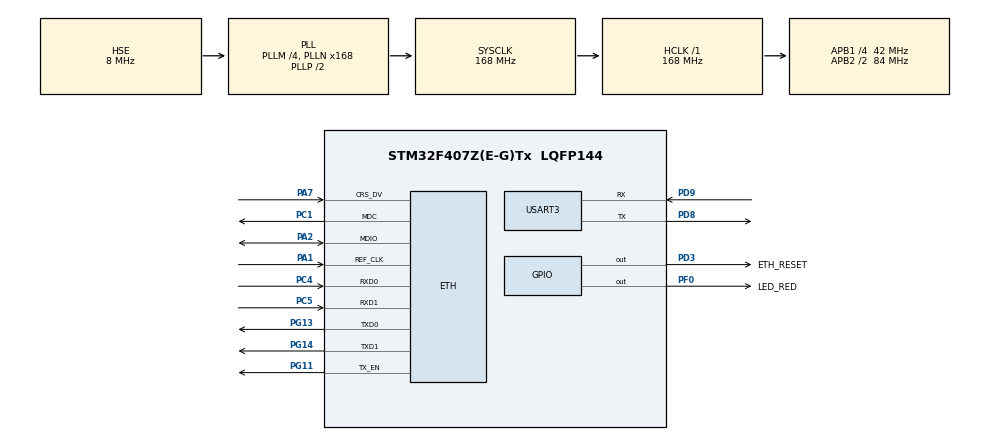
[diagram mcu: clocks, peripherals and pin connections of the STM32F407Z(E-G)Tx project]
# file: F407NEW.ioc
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ETH.MediaInterface=ETH_MEDIA_INTERFACE_RMII
ETH.PHY_Name_RMII=userPHY
ETH.PHY_User_Name=LAN8720A
ETH.PhyAddress=0
FREERTOS.Tasks01=SCI,3,256,SCI_FUNC,Default,NULL,Dynamic,NULL,NULL;NET,3,256,NET_FUNC,Default,NULL,Dynamic,NULL,NULL;LED,-2,128,LED_FUNC,Default,NULL,Dynamic,NULL,NULL
FREERTOS.configMAX_PRIORITIES=12
FREERTOS.configTOTAL_HEAP_SIZE=49152
LWIP.GATEWAY_ADDRESS=192.168.001.001
LWIP.IP_ADDRESS=192.168.001.028
LWIP.LWIP_DHCP=0
LWIP.LWIP_NETIF_LINK_CALLBACK=1
LWIP.LWIP_NETIF_STATUS_CALLBACK=1
LWIP.LWIP_UDP=0
LWIP.NETMASK_ADDRESS=255.255.255.000
LWIP.Version=v2.0.3_Cube
Mcu.Family=STM32F4
Mcu.Name=STM32F407Z(E-G)Tx
Mcu.Package=LQFP144
NVIC.ETH_IRQn=true\:5\:0\:true\:false\:true\:true\:true\:true
NVIC.PriorityGroup=NVIC_PRIORITYGROUP_4
NVIC.TIM1_UP_TIM10_IRQn=true\:0\:0\:false\:false\:true\:false\:false\:true
NVIC.TimeBase=TIM1_UP_TIM10_IRQn
NVIC.TimeBaseIP=TIM1
NVIC.USART3_IRQn=true\:5\:0\:true\:false\:true\:true\:true\:true
PA1.Mode=RMII
PA1.Signal=ETH_REF_CLK
PA13.Mode=Serial_Wire
PA13.Signal=SYS_JTMS-SWDIO
PA14.Mode=Serial_Wire
PA14.Signal=SYS_JTCK-SWCLK
PA2.Mode=RMII
PA2.Signal=ETH_MDIO
PA7.Mode=RMII
PA7.Signal=ETH_CRS_DV
PB11.Signal=S_TIM2_CH4
PC1.Mode=RMII
PC1.Signal=ETH_MDC
PC4.Mode=RMII
PC4.Signal=ETH_RXD0
PC5.Mode=RMII
PC5.Signal=ETH_RXD1
PD3.GPIO_Label=ETH_RESET
PD3.GPIO_Speed=GPIO_SPEED_FREQ_VERY_HIGH
PD3.PinState=GPIO_PIN_SET
PD3.Signal=GPIO_Output
PD8.Mode=Asynchronous
PD8.Signal=USART3_TX
PD9.Mode=Asynchronous
PD9.Signal=USART3_RX
PF0.GPIO_Label=LED_RED
PF0.Signal=GPIO_Output
PG11.Mode=RMII
PG11.Signal=ETH_TX_EN
PG13.Mode=RMII
PG13.Signal=ETH_TXD0
PG14.Mode=RMII
PG14.Signal=ETH_TXD1
PH0-OSC_IN.Mode=HSE-External-Oscillator
PH0-OSC_IN.Signal=RCC_OSC_IN
PH1-OSC_OUT.Mode=HSE-External-Oscillator
PH1-OSC_OUT.Signal=RCC_OSC_OUT
ProjectManager.HeapSize=0x200
ProjectManager.StackSize=0x4000
ProjectManager.TargetToolchain=MDK-ARM V5
RCC.48MHZClocksFreq_Value=84000000
RCC.AHBFreq_Value=168000000
RCC.APB1CLKDivider=RCC_HCLK_DIV4
RCC.APB1Freq_Value=42000000
RCC.APB1TimFreq_Value=84000000
RCC.APB2CLKDivider=RCC_HCLK_DIV2
RCC.APB2Freq_Value=84000000
RCC.APB2TimFreq_Value=168000000
RCC.CortexFreq_Value=168000000
RCC.HCLKFreq_Value=168000000
RCC.HSE_VALUE=8000000
RCC.HSI_VALUE=16000000
RCC.LSE_VALUE=32768
RCC.PLLM=4
RCC.PLLN=168
RCC.PLLSourceVirtual=RCC_PLLSOURCE_HSE
RCC.SYSCLKFreq_VALUE=168000000
RCC.SYSCLKSource=RCC_SYSCLKSOURCE_PLLCLK
RCC.VCOOutputFreq_Value=336000000
SH.S_TIM2_CH4.0=TIM2_CH4
USART3.VirtualMode=VM_ASYNC
VP_FREERTOS_VS_CMSIS_V1.Mode=CMSIS_V1
VP_LWIP_VS_Enabled.Mode=Enabled
VP_SYS_VS_tim1.Mode=TIM1
board=custom

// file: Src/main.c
/* USER CODE BEGIN Header */
/**
  ******************************************************************************
  * @file           : main.c
  * @brief          : Main program body
  ******************************************************************************
  * @attention
  *
  * <h2><center>&copy; Copyright (c) 2025 STMicroelectronics.
  * All rights reserved.</center></h2>
  *
  * This software component is licensed by ST under Ultimate Liberty license
  * SLA0044, the "License"; You may not use this file except in compliance with
  * the License. You may obtain a copy of the License at:
  *                             www.st.com/SLA0044
  *
  ******************************************************************************
  */
/* USER CODE END Header */

#include "main.h"
#include "cmsis_os.h"
#include "lwip.h"
#include "usart.h"
#include "gpio.h"

/* USER CODE BEGIN Includes */
#include <string.h>

/* USER CODE END Includes */

/* USER CODE BEGIN PV */

// #define RXBUFFERSIZE  256     //最大接收字节数
// char RxBuffer[RXBUFFERSIZE];   //接收数据
// uint8_t aRxBuffer;			//接收中断缓冲
// uint8_t Uart3_Rx_Cnt = 0;		//接收缓冲计数

/* USER CODE END PV */

void SystemClock_Config(void);
void MX_FREERTOS_Init(void);

int main(void)
{

  /* MCU Configuration--------------------------------------------------------*/

  /* Reset of all peripherals, Initializes the Flash interface and the Systick. */
  HAL_Init();

  /* Configure the system clock */
  SystemClock_Config();

  /* Initialize all configured peripherals */
  MX_GPIO_Init();
  MX_USART3_UART_Init();
  /* USER CODE BEGIN 2 */

	// HAL_UART_Receive_IT(&huart3, (uint8_t *)&aRxBuffer, 1);
  /* init code for LWIP */
  MX_LWIP_Init();
	tcpecho_init();
	printf("RTOS_LWIP: Start\r\n");

  /* USER CODE END 2 */

  /* Call init function for freertos objects (in freertos.c) */
  MX_FREERTOS_Init();

  /* Start scheduler */
  osKernelStart();

  /* We should never get here as control is now taken by the scheduler */

  /* Infinite loop */
  while (1)
  {

  }
}

void SystemClock_Config(void)
{
  RCC_OscInitTypeDef RCC_OscInitStruct = {0};
  RCC_ClkInitTypeDef RCC_ClkInitStruct = {0};

  /** Configure the main internal regulator output voltage
  */
  __HAL_RCC_PWR_CLK_ENABLE();
  __HAL_PWR_VOLTAGESCALING_CONFIG(PWR_REGULATOR_VOLTAGE_SCALE1);
  /** Initializes the CPU, AHB and APB busses clocks
  */
  RCC_OscInitStruct.OscillatorType = RCC_OSCILLATORTYPE_HSE;
  RCC_OscInitStruct.HSEState = RCC_HSE_ON;
  RCC_OscInitStruct.PLL.PLLState = RCC_PLL_ON;
  RCC_OscInitStruct.PLL.PLLSource = RCC_PLLSOURCE_HSE;
  RCC_OscInitStruct.PLL.PLLM = 4;
  RCC_OscInitStruct.PLL.PLLN = 168;
  RCC_OscInitStruct.PLL.PLLP = RCC_PLLP_DIV2;
  RCC_OscInitStruct.PLL.PLLQ = 4;
  if (HAL_RCC_OscConfig(&RCC_OscInitStruct) != HAL_OK)
  {
    Error_Handler();
  }
  /** Initializes the CPU, AHB and APB busses clocks
  */
  RCC_ClkInitStruct.ClockType = RCC_CLOCKTYPE_HCLK|RCC_CLOCKTYPE_SYSCLK
                              |RCC_CLOCKTYPE_PCLK1|RCC_CLOCKTYPE_PCLK2;
  RCC_ClkInitStruct.SYSCLKSource = RCC_SYSCLKSOURCE_PLLCLK;
  RCC_ClkInitStruct.AHBCLKDivider = RCC_SYSCLK_DIV1;
  RCC_ClkInitStruct.APB1CLKDivider = RCC_HCLK_DIV4;
  RCC_ClkInitStruct.APB2CLKDivider = RCC_HCLK_DIV2;

  if (HAL_RCC_ClockConfig(&RCC_ClkInitStruct, FLASH_LATENCY_5) != HAL_OK)
  {
    Error_Handler();
  }
}

/* USER CODE BEGIN 4 */

void HAL_UART_RxCpltCallback(UART_HandleTypeDef *huart)
{
  /* Prevent unused argument(s) compilation warning */

	// if(Uart3_Rx_Cnt >= 255)  //溢出判断
	// {
	//  Uart3_Rx_Cnt = 0;
	//  memset(RxBuffer,0x00,sizeof(RxBuffer));
	//  HAL_UART_Transmit(&huart3, (uint8_t *)"数据溢出", 10,0xFFFF);
	// }
	// else
	// {
	//  RxBuffer[Uart3_Rx_Cnt++] = aRxBuffer;   //接收数据转存

	//  if((RxBuffer[Uart3_Rx_Cnt-1] == 0x0A)&&(RxBuffer[Uart3_Rx_Cnt-2] == 0x0D)) //判断结束位
	//  {
	// 	 HAL_UART_Transmit(&huart3, (uint8_t *)&RxBuffer, Uart3_Rx_Cnt,0xFFFF); //将收到的信息发送出去
	// 	 while(HAL_UART_GetState(&huart3) == HAL_UART_STATE_BUSY_TX);//检测UART发送结束
	// 	 Uart3_Rx_Cnt = 0;
	// 	 memset(RxBuffer,0x00,sizeof(RxBuffer)); //清空数组
	//  }
	// }
	// HAL_UART_Receive_IT(&huart3, (uint8_t *)&aRxBuffer, 1);   //再开启接收中断

}
/* USER CODE END 4 */

void HAL_TIM_PeriodElapsedCallback(TIM_HandleTypeDef *htim)
{
  if (htim->Instance == TIM1) {
    HAL_IncTick();
  }
}

void Error_Handler(void)
{
}

/************************ (C) COPYRIGHT STMicroelectronics *****END OF FILE****/

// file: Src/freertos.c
/* USER CODE BEGIN Header */
/**
  ******************************************************************************
  * File Name          : freertos.c
  * Description        : Code for freertos applications
  ******************************************************************************
  * @attention
  *
  * <h2><center>&copy; Copyright (c) 2025 STMicroelectronics.
  * All rights reserved.</center></h2>
  *
  * This software component is licensed by ST under Ultimate Liberty license
  * SLA0044, the "License"; You may not use this file except in compliance with
  * the License. You may obtain a copy of the License at:
  *                             www.st.com/SLA0044
  *
  ******************************************************************************
  */
/* USER CODE END Header */

#include "FreeRTOS.h"
#include "task.h"
#include "main.h"
#include "cmsis_os.h"

/* USER CODE BEGIN PM */
// extern char RxBuffer[256];   //接收数据
// extern uint8_t aRxBuffer;			//接收中断缓冲
// extern uint8_t Uart3_Rx_Cnt;		//接收缓冲计数
/* USER CODE END PM */

osThreadId LEDHandle;
osThreadId NETHandle;

/* USER CODE BEGIN FunctionPrototypes */
int num = 0;
/* USER CODE END FunctionPrototypes */

void LED_FUNC(void const * argument);
void NET_FUNC(void const * argument);

extern void MX_LWIP_Init(void);
void MX_FREERTOS_Init(void); /* (MISRA C 2004 rule 8.1) */

/* GetIdleTaskMemory prototype (linked to static allocation support) */
void vApplicationGetIdleTaskMemory( StaticTask_t **ppxIdleTaskTCBBuffer, StackType_t **ppxIdleTaskStackBuffer, uint32_t *pulIdleTaskStackSize );

/* USER CODE BEGIN GET_IDLE_TASK_MEMORY */
static StaticTask_t xIdleTaskTCBBuffer;
static StackType_t xIdleStack[configMINIMAL_STACK_SIZE];

void vApplicationGetIdleTaskMemory( StaticTask_t **ppxIdleTaskTCBBuffer, StackType_t **ppxIdleTaskStackBuffer, uint32_t *pulIdleTaskStackSize )
{
  *ppxIdleTaskTCBBuffer = &xIdleTaskTCBBuffer;
  *ppxIdleTaskStackBuffer = &xIdleStack[0];
  *pulIdleTaskStackSize = configMINIMAL_STACK_SIZE;
  /* place for user code */
}
/* USER CODE END GET_IDLE_TASK_MEMORY */

void MX_FREERTOS_Init(void) {

  /* Create the thread(s) */
  /* definition and creation of LED */
  osThreadDef(LED, LED_FUNC, osPriorityLow, 0, 128);
  LEDHandle = osThreadCreate(osThread(LED), NULL);

  /* definition and creation of NET */
  osThreadDef(NET, NET_FUNC, osPriorityRealtime, 0, 256);
  NETHandle = osThreadCreate(osThread(NET), NULL);

}

void LED_FUNC(void const * argument)
{
  /* USER CODE BEGIN LED_FUNC */
  /* Infinite loop */
  for(;;)
  {
		HAL_GPIO_TogglePin(LED_RED_GPIO_Port, LED_YELLOW_Pin);
    osDelay(1000);
  }
  /* USER CODE END LED_FUNC */
}

void NET_FUNC(void const * argument)
{
  /* USER CODE BEGIN NET_FUNC */
  /* Infinite loop */
  for(;;)
  {
  if(num == 0x55){
	//if(num == 0){
    HAL_GPIO_WritePin(LED_GREEN_GPIO_Port, LED_RED_Pin, GPIO_PIN_SET);//turn off
  }else if(num == 0xcc)
	//}else if(num == 1)
	{
    HAL_GPIO_WritePin(LED_GREEN_GPIO_Port, LED_RED_Pin, GPIO_PIN_RESET);//turn on
  }
    osDelay(1);
  }
  /* USER CODE END NET_FUNC */
}

/************************ (C) COPYRIGHT STMicroelectronics *****END OF FILE****/
